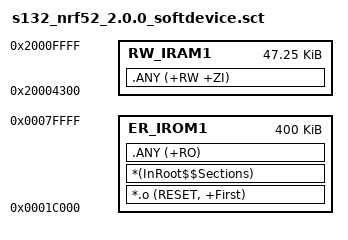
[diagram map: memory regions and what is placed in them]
; *************************************************************
; *** Scatter-Loading Description File generated by uVision ***
; *************************************************************

LR_IROM1 0x0001C000 0x00064000  {    ; load region size_region
  ER_IROM1 0x0001C000 0x00064000  {  ; load address = execution address
   *.o (RESET, +First)
   *(InRoot$$Sections)
   .ANY (+RO)
  }
  RW_IRAM1 0x20004300 0x0000BD00  {  ; RW data
   .ANY (+RW +ZI)
  }
}

